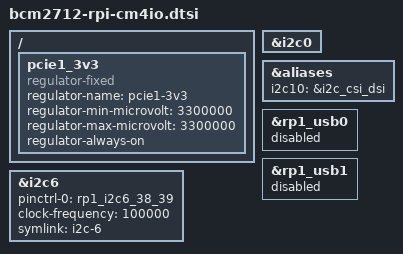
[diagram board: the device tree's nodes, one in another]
// SPDX-License-Identifier: GPL-2.0

/ {
	/*
	 * The CM4IO PCIe slot supply is not switched. This only exists so that
	 * overlays written for the Pi 5 (pciex1-compat-pi5) can resolve it.
	 */
	pcie1_3v3: pcie1_3v3 {
		compatible = "regulator-fixed";
		regulator-name = "pcie1-3v3";
		regulator-min-microvolt = <3300000>;
		regulator-max-microvolt = <3300000>;
		regulator-always-on;
	};
};

i2c_csi_dsi0: &i2c0 { // Note: For CAM0 and DISP0 connectors
};

i2c_csi_dsi1: &i2c6 { // Note: For CAM1, DISP1, on-board RTC, and fan controller
	pinctrl-0 = <&rp1_i2c6_38_39>;
	pinctrl-names = "default";
	clock-frequency = <100000>;
	symlink = "i2c-6";
};

i2c_csi_dsi: &i2c_csi_dsi1 { }; // The connector that needs no jumper to enable

&aliases {
    /delete-property/ i2c11;
    i2c10 = &i2c_csi_dsi;
};

// The RP1 USB3 interfaces are not usable on CM4IO

&rp1_usb0 {
	status = "disabled";
};

&rp1_usb1 {
	status = "disabled";
};
